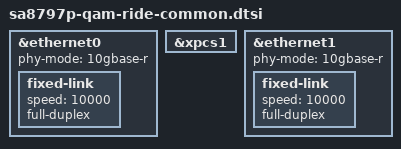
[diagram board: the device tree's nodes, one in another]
// SPDX-License-Identifier: BSD-3-Clause
/*
 * Copyright (c) 2024-2025 Qualcomm Innovation Center, Inc. All rights reserved.
 */

#include "qam8797p.dtsi"

&ethernet0 {
	phy-mode = "10gbase-r";

	fixed-link {
		status = "okay";
		speed = <10000>;
		full-duplex;
	};
};

&xpcs1 {
	status = "okay";
};

&ethernet1 {
	status = "okay";
	phy-mode = "10gbase-r";

	fixed-link {
		status = "okay";
		speed = <10000>;
		full-duplex;
	};
};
